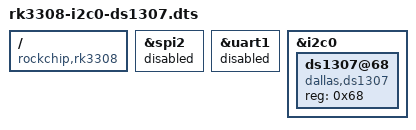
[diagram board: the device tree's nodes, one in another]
/dts-v1/;
/plugin/;

/ {
	compatible = "rockchip,rk3308";

	fragment@0 {
		target = <&spi2>;
		__overlay__ {
			status = "disabled";
		};
	};

	fragment@1 {
		target = <&uart1>;
		__overlay__ {
			status = "disabled";
		};
	};

	fragment@2 {
		target = <&i2c0>;
		__overlay__ {
			status = "okay";
			ds1307@68 {
				compatible = "dallas,ds1307";
				reg = <0x68>;
				status = "okay";
			};
		};
	};
};
